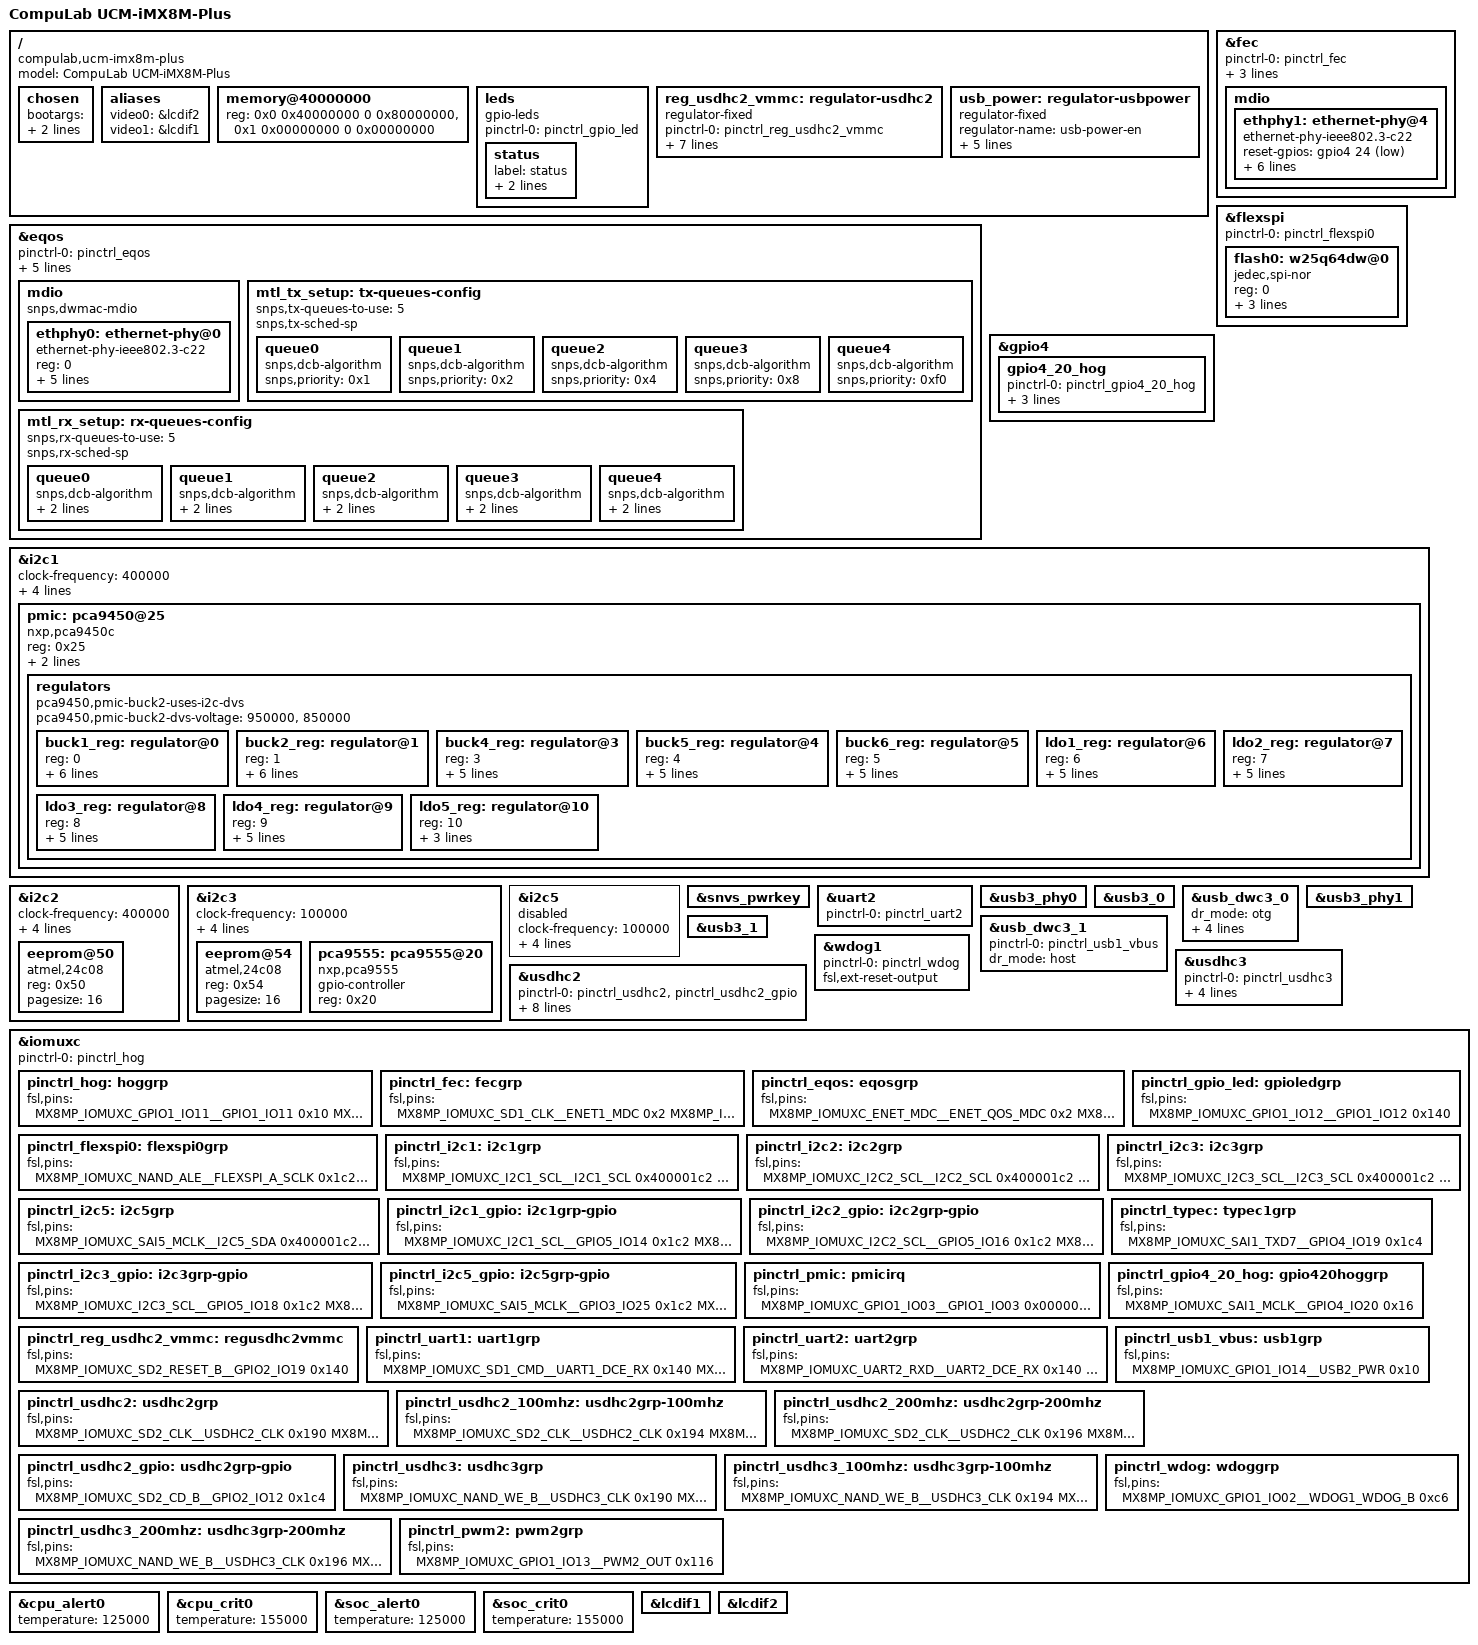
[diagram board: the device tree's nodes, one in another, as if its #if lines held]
// SPDX-License-Identifier: (GPL-2.0+ OR MIT)
/*
 * Copyright 2021 CompuLab
 */

/dts-v1/;

#include <dt-bindings/usb/pd.h>
#include "imx8mp.dtsi"

/ {
	model = "CompuLab UCM-iMX8M-Plus";
	compatible = "compulab,ucm-imx8m-plus", "fsl,imx8mp";

	chosen {
		bootargs = "console=ttymxc1,115200 earlycon=ec_imx6q,0x30890000,115200 console=tty0";
		stdout-path = &uart2;
	};
	aliases {
		video0 = &lcdif2;
		video1 = &lcdif1;
	};

	memory@40000000 {
		device_type = "memory";
		reg = <0x0 0x40000000 0 0x80000000>,
		      <0x1 0x00000000 0 0x00000000>;
	};

	leds {
		compatible = "gpio-leds";
		pinctrl-names = "default";
		pinctrl-0 = <&pinctrl_gpio_led>;

		status {
			label = "status";
			gpios = <&gpio1 12 GPIO_ACTIVE_LOW>;
			default-state = "on"; /* LED GREEN */
		};
	};

	reg_usdhc2_vmmc: regulator-usdhc2 {
		compatible = "regulator-fixed";
		pinctrl-names = "default";
		pinctrl-0 = <&pinctrl_reg_usdhc2_vmmc>;
		regulator-name = "VSD_3V3";
		regulator-min-microvolt = <3300000>;
		regulator-max-microvolt = <3300000>;
		gpio = <&gpio2 19 GPIO_ACTIVE_HIGH>;
		enable-active-high;
		startup-delay-us = <100>;
		off-on-delay-us = <12000>;
	};
#ifdef CONFIG_SBEV_UCMIMX8PLUS
	usb_power: regulator-usbpower {
		compatible = "regulator-fixed";
		regulator-name = "usb-power-en";
		regulator-min-microvolt = <3300000>;
		regulator-max-microvolt = <3300000>;
		gpio = <&pca9555 1 GPIO_ACTIVE_HIGH>;
		enable-active-high;
		regulator-always-on;
	};
#endif
};

&fec {
	pinctrl-names = "default";
	pinctrl-0 = <&pinctrl_fec>;
	phy-mode = "rgmii-rxid";
	phy-handle = <&ethphy1>;
	fsl,magic-packet;
	status = "okay";

	mdio {
		#address-cells = <1>;
		#size-cells = <0>;

		ethphy1: ethernet-phy@4 {
			compatible = "ethernet-phy-ieee802.3-c22";
			reset-gpios = <&gpio4 24 GPIO_ACTIVE_LOW>;
			reg = <4>;
			reset-assert-us = <10000>;
			reset-deassert-us = <80000>;
			eee-broken-1000t;
			realtek,aldps-enable;
			realtek,clkout-disable;
		};
	};
};

&eqos {
	pinctrl-names = "default";
	pinctrl-0 = <&pinctrl_eqos>;
	phy-mode = "rgmii-id";
	phy-handle = <&ethphy0>;
	snps,force_thresh_dma_mode;
	snps,mtl-tx-config = <&mtl_tx_setup>;
	snps,mtl-rx-config = <&mtl_rx_setup>;
	status = "okay";

	mdio {
		compatible = "snps,dwmac-mdio";
		#address-cells = <1>;
		#size-cells = <0>;

		ethphy0: ethernet-phy@0 {
			compatible = "ethernet-phy-ieee802.3-c22";
			reg = <0>;
			eee-broken-1000t;
			reset-gpios = <&gpio1 10 GPIO_ACTIVE_LOW>;
			reset-assert-us = <15000>;
			reset-deassert-us = <100000>;
			realtek,clkout-disable;
		};
	};

	mtl_tx_setup: tx-queues-config {
		snps,tx-queues-to-use = <5>;
		snps,tx-sched-sp;

		queue0 {
			snps,dcb-algorithm;
			snps,priority = <0x1>;
		};

		queue1 {
			snps,dcb-algorithm;
			snps,priority = <0x2>;
		};

		queue2 {
			snps,dcb-algorithm;
			snps,priority = <0x4>;
		};

		queue3 {
			snps,dcb-algorithm;
			snps,priority = <0x8>;
		};

		queue4 {
			snps,dcb-algorithm;
			snps,priority = <0xf0>;
		};
	};

	mtl_rx_setup: rx-queues-config {
		snps,rx-queues-to-use = <5>;
		snps,rx-sched-sp;

		queue0 {
			snps,dcb-algorithm;
			snps,priority = <0x1>;
			snps,map-to-dma-channel = <0>;
		};

		queue1 {
			snps,dcb-algorithm;
			snps,priority = <0x2>;
			snps,map-to-dma-channel = <1>;
		};

		queue2 {
			snps,dcb-algorithm;
			snps,priority = <0x4>;
			snps,map-to-dma-channel = <2>;
		};

		queue3 {
			snps,dcb-algorithm;
			snps,priority = <0x8>;
			snps,map-to-dma-channel = <3>;
		};

		queue4 {
			snps,dcb-algorithm;
			snps,priority = <0xf0>;
			snps,map-to-dma-channel = <4>;
		};
	};
};

&flexspi {
	pinctrl-names = "default";
	pinctrl-0 = <&pinctrl_flexspi0>;
	status = "okay";

	flash0: w25q64dw@0 {
		reg = <0>;
		#address-cells = <1>;
		#size-cells = <1>;
		compatible = "jedec,spi-nor";
		spi-max-frequency = <80000000>;
		spi-tx-bus-width = <4>;
		spi-rx-bus-width = <4>;
	};
};

&gpio4 {
	gpio4_20_hog {
		pinctrl-names = "default";
		pinctrl-0 = <&pinctrl_gpio4_20_hog>;
		gpio-hog;
		gpios = <20 GPIO_ACTIVE_HIGH>;
		output-high;
	};
};

&i2c1 {
	clock-frequency = <400000>;
	pinctrl-names = "default", "gpio";
	pinctrl-0 = <&pinctrl_i2c1>;
	pinctrl-1 = <&pinctrl_i2c1_gpio>;
	scl-gpios = <&gpio5 14 GPIO_ACTIVE_HIGH>;
	sda-gpios = <&gpio5 15 GPIO_ACTIVE_HIGH>;
	status = "okay";

	pmic: pca9450@25 {
		reg = <0x25>;
		compatible = "nxp,pca9450c";
		/* PMIC PCA9450 PMIC_nINT GPIO1_IO3 */
		pinctrl-0 = <&pinctrl_pmic>;
		gpio_intr = <&gpio1 3 GPIO_ACTIVE_LOW>;

		regulators {
			#address-cells = <1>;
			#size-cells = <0>;

			pca9450,pmic-buck2-uses-i2c-dvs;
			/* Run/Standby voltage */
			pca9450,pmic-buck2-dvs-voltage = <950000>, <850000>;

			buck1_reg: regulator@0 {
				reg = <0>;
				regulator-compatible = "buck1";
				regulator-min-microvolt = <600000>;
				regulator-max-microvolt = <2187500>;
				regulator-boot-on;
				regulator-always-on;
				regulator-ramp-delay = <3125>;
			};

			buck2_reg: regulator@1 {
				reg = <1>;
				regulator-compatible = "buck2";
				regulator-min-microvolt = <600000>;
				regulator-max-microvolt = <2187500>;
				regulator-boot-on;
				regulator-always-on;
				regulator-ramp-delay = <3125>;
			};

			buck4_reg: regulator@3 {
				reg = <3>;
				regulator-compatible = "buck4";
				regulator-min-microvolt = <600000>;
				regulator-max-microvolt = <3400000>;
				regulator-boot-on;
				regulator-always-on;
			};

			buck5_reg: regulator@4 {
				reg = <4>;
				regulator-compatible = "buck5";
				regulator-min-microvolt = <600000>;
				regulator-max-microvolt = <3400000>;
				regulator-boot-on;
				regulator-always-on;
			};

			buck6_reg: regulator@5 {
				reg = <5>;
				regulator-compatible = "buck6";
				regulator-min-microvolt = <600000>;
				regulator-max-microvolt = <3400000>;
				regulator-boot-on;
				regulator-always-on;
			};

			ldo1_reg: regulator@6 {
				reg = <6>;
				regulator-compatible = "ldo1";
				regulator-min-microvolt = <1600000>;
				regulator-max-microvolt = <3300000>;
				regulator-boot-on;
				regulator-always-on;
			};

			ldo2_reg: regulator@7 {
				reg = <7>;
				regulator-compatible = "ldo2";
				regulator-min-microvolt = <800000>;
				regulator-max-microvolt = <1150000>;
				regulator-boot-on;
				regulator-always-on;
			};

			ldo3_reg: regulator@8 {
				reg = <8>;
				regulator-compatible = "ldo3";
				regulator-min-microvolt = <800000>;
				regulator-max-microvolt = <3300000>;
				regulator-boot-on;
				regulator-always-on;
			};

			ldo4_reg: regulator@9 {
				reg = <9>;
				regulator-compatible = "ldo4";
				regulator-min-microvolt = <800000>;
				regulator-max-microvolt = <1800000>;
				regulator-boot-on;
				regulator-always-on;
			};

			ldo5_reg: regulator@10 {
				reg = <10>;
				regulator-compatible = "ldo5";
				regulator-min-microvolt = <1800000>;
				regulator-max-microvolt = <3300000>;
			};
		};
	};
};

&i2c2 {
	clock-frequency = <400000>;
	pinctrl-names = "default", "gpio";
	pinctrl-0 = <&pinctrl_i2c2>;
	pinctrl-1 = <&pinctrl_i2c2_gpio>;
	scl-gpios = <&gpio5 16 GPIO_ACTIVE_HIGH>;
	sda-gpios = <&gpio5 17 GPIO_ACTIVE_HIGH>;
	status = "okay";

	eeprom@50 {
		compatible = "atmel,24c08";
		reg = <0x50>;
		pagesize = <16>;
	};
};

&i2c3 {
	clock-frequency = <100000>;
	pinctrl-names = "default", "gpio";
	pinctrl-0 = <&pinctrl_i2c3>;
	pinctrl-1 = <&pinctrl_i2c3_gpio>;
	scl-gpios = <&gpio5 18 GPIO_ACTIVE_HIGH>;
	sda-gpios = <&gpio5 19 GPIO_ACTIVE_HIGH>;
	status = "okay";

};

#ifdef CONFIG_SBEV_UCMIMX8PLUS
&i2c3
#else
&i2c2
#endif
{
	eeprom@54 {
		compatible = "atmel,24c08";
		reg = <0x54>;
		pagesize = <16>;
	};

	pca9555:pca9555@20 {
		compatible = "nxp,pca9555";
		gpio-controller;
		#gpio-cells = <2>;
		reg = <0x20>;
	};
};

&i2c5 {
	clock-frequency = <100000>;
	pinctrl-names = "default", "gpio";
	pinctrl-0 = <&pinctrl_i2c5>;
	pinctrl-1 = <&pinctrl_i2c5_gpio>;
	scl-gpios = <&gpio3 21 GPIO_ACTIVE_HIGH>;
	sda-gpios = <&gpio3 25 GPIO_ACTIVE_HIGH>;
	status = "disabled";

};

&snvs_pwrkey {
	status = "okay";
};

&uart2 {
	/* console */
	pinctrl-names = "default";
	pinctrl-0 = <&pinctrl_uart2>;
	status = "okay";
};

&usb3_phy0 {
	status = "okay";
};

&usb3_0 {
	status = "okay";
};

&usb_dwc3_0 {
	dr_mode = "otg";
	hnp-disable;
	srp-disable;
	adp-disable;
	usb-role-switch;
	status = "okay";
};

&usb3_phy1 {
	status = "okay";
};

&usb3_1 {
	status = "okay";
};

&usb_dwc3_1 {
	pinctrl-names = "default";
	pinctrl-0 = <&pinctrl_usb1_vbus>;
	dr_mode = "host";
	status = "okay";
};

&usdhc2 {
	pinctrl-names = "default", "state_100mhz", "state_200mhz";
	pinctrl-0 = <&pinctrl_usdhc2>, <&pinctrl_usdhc2_gpio>;
	pinctrl-1 = <&pinctrl_usdhc2_100mhz>, <&pinctrl_usdhc2_gpio>;
	pinctrl-2 = <&pinctrl_usdhc2_200mhz>, <&pinctrl_usdhc2_gpio>;
	cd-gpios = <&gpio2 12 GPIO_ACTIVE_LOW>;
	vmmc-supply = <&reg_usdhc2_vmmc>;
	bus-width = <4>;
	no-1-8-v;
	status = "okay";
};

&usdhc3 {
	pinctrl-names = "default", "state_100mhz", "state_200mhz";
	pinctrl-0 = <&pinctrl_usdhc3>;
	pinctrl-1 = <&pinctrl_usdhc3_100mhz>;
	pinctrl-2 = <&pinctrl_usdhc3_200mhz>;
	bus-width = <8>;
	non-removable;
	status = "okay";
};

&wdog1 {
	pinctrl-names = "default";
	pinctrl-0 = <&pinctrl_wdog>;
	fsl,ext-reset-output;
	status = "okay";
};

&iomuxc {
	pinctrl-names = "default";
	pinctrl-0 = <&pinctrl_hog>;

	pinctrl_hog: hoggrp {
		fsl,pins = <
			MX8MP_IOMUXC_GPIO1_IO11__GPIO1_IO11	0x10
			MX8MP_IOMUXC_GPIO1_IO13__GPIO1_IO13	0x10
		>;
	};

	pinctrl_fec: fecgrp {
		fsl,pins = <
			MX8MP_IOMUXC_SD1_CLK__ENET1_MDC			0x2
			MX8MP_IOMUXC_SD1_CMD__ENET1_MDIO		0x2
			MX8MP_IOMUXC_SD1_DATA1__ENET1_RGMII_TD0		0x16
			MX8MP_IOMUXC_SD1_DATA0__ENET1_RGMII_TD1		0x16
			MX8MP_IOMUXC_SAI1_TXD2__ENET1_RGMII_TD2		0x16
			MX8MP_IOMUXC_SAI1_TXD3__ENET1_RGMII_TD3		0x16
			MX8MP_IOMUXC_SAI1_TXD4__ENET1_RGMII_TX_CTL	0x16
			MX8MP_IOMUXC_SAI1_TXD5__ENET1_RGMII_TXC		0x16

			MX8MP_IOMUXC_SD1_DATA2__ENET1_RGMII_RD0		0x90
			MX8MP_IOMUXC_SD1_DATA3__ENET1_RGMII_RD1		0x90
			MX8MP_IOMUXC_SAI1_RXD6__ENET1_RGMII_RD2		0x90
			MX8MP_IOMUXC_SAI1_RXD7__ENET1_RGMII_RD3		0x90
			MX8MP_IOMUXC_SAI1_TXC__ENET1_RGMII_RXC		0x90
			MX8MP_IOMUXC_SAI1_TXFS__ENET1_RGMII_RX_CTL	0x90

			/* gpio */
			MX8MP_IOMUXC_SAI2_RXFS__GPIO4_IO21		0x10 /* INT */
			MX8MP_IOMUXC_SAI2_TXFS__GPIO4_IO24		0x10 /* RST */
		>;
	};

	pinctrl_eqos: eqosgrp {
		fsl,pins = <
			MX8MP_IOMUXC_ENET_MDC__ENET_QOS_MDC	0x2
			MX8MP_IOMUXC_ENET_MDIO__ENET_QOS_MDIO	0x2
			MX8MP_IOMUXC_ENET_RD0__ENET_QOS_RGMII_RD0	0x90
			MX8MP_IOMUXC_ENET_RD1__ENET_QOS_RGMII_RD1	0x90
			MX8MP_IOMUXC_ENET_RD2__ENET_QOS_RGMII_RD2	0x90
			MX8MP_IOMUXC_ENET_RD3__ENET_QOS_RGMII_RD3	0x90
			MX8MP_IOMUXC_ENET_RXC__CCM_ENET_QOS_CLOCK_GENERATE_RX_CLK	0x90
			MX8MP_IOMUXC_ENET_RX_CTL__ENET_QOS_RGMII_RX_CTL	0x90
			MX8MP_IOMUXC_ENET_TD0__ENET_QOS_RGMII_TD0		0x16
			MX8MP_IOMUXC_ENET_TD1__ENET_QOS_RGMII_TD1		0x16
			MX8MP_IOMUXC_ENET_TD2__ENET_QOS_RGMII_TD2		0x16
			MX8MP_IOMUXC_ENET_TD3__ENET_QOS_RGMII_TD3		0x16
			MX8MP_IOMUXC_ENET_TX_CTL__ENET_QOS_RGMII_TX_CTL	0x16
			MX8MP_IOMUXC_ENET_TXC__CCM_ENET_QOS_CLOCK_GENERATE_TX_CLK	0x16
			MX8MP_IOMUXC_GPIO1_IO10__GPIO1_IO10	0x10
		>;
	};

	pinctrl_flexspi0: flexspi0grp {
		fsl,pins = <
			MX8MP_IOMUXC_NAND_ALE__FLEXSPI_A_SCLK		0x1c2
			MX8MP_IOMUXC_NAND_CE0_B__FLEXSPI_A_SS0_B	0x82
			MX8MP_IOMUXC_NAND_DATA00__FLEXSPI_A_DATA00	0x82
			MX8MP_IOMUXC_NAND_DATA01__FLEXSPI_A_DATA01	0x82
			MX8MP_IOMUXC_NAND_DATA02__FLEXSPI_A_DATA02	0x82
			MX8MP_IOMUXC_NAND_DATA03__FLEXSPI_A_DATA03	0x82
		>;
	};

	pinctrl_gpio_led: gpioledgrp {
		fsl,pins = <
			MX8MP_IOMUXC_GPIO1_IO12__GPIO1_IO12	0x140
		>;
	};

	pinctrl_i2c1: i2c1grp {
		fsl,pins = <
			MX8MP_IOMUXC_I2C1_SCL__I2C1_SCL		0x400001c2
			MX8MP_IOMUXC_I2C1_SDA__I2C1_SDA		0x400001c2
		>;
	};

	pinctrl_i2c2: i2c2grp {
		fsl,pins = <
			MX8MP_IOMUXC_I2C2_SCL__I2C2_SCL			0x400001c2
			MX8MP_IOMUXC_I2C2_SDA__I2C2_SDA			0x400001c2
		>;
	};

	pinctrl_i2c3: i2c3grp {
		fsl,pins = <
			MX8MP_IOMUXC_I2C3_SCL__I2C3_SCL			0x400001c2
			MX8MP_IOMUXC_I2C3_SDA__I2C3_SDA			0x400001c2
		>;
	};

	pinctrl_i2c5: i2c5grp {
		fsl,pins = <
			MX8MP_IOMUXC_SAI5_MCLK__I2C5_SDA		0x400001c2
			MX8MP_IOMUXC_SAI5_RXD0__I2C5_SCL		0x400001c2
		>;
	};

	pinctrl_i2c1_gpio: i2c1grp-gpio {
		fsl,pins = <
			MX8MP_IOMUXC_I2C1_SCL__GPIO5_IO14        	0x1c2
			MX8MP_IOMUXC_I2C1_SDA__GPIO5_IO15        	0x1c2
		>;
	};

	pinctrl_i2c2_gpio: i2c2grp-gpio {
		fsl,pins = <
			MX8MP_IOMUXC_I2C2_SCL__GPIO5_IO16        	0x1c2
			MX8MP_IOMUXC_I2C2_SDA__GPIO5_IO17        	0x1c2
		>;
	};

	pinctrl_i2c3_gpio: i2c3grp-gpio {
		fsl,pins = <
			MX8MP_IOMUXC_I2C3_SCL__GPIO5_IO18        	0x1c2
			MX8MP_IOMUXC_I2C3_SDA__GPIO5_IO19        	0x1c2
		>;
	};

	pinctrl_i2c5_gpio: i2c5grp-gpio {
		fsl,pins = <
			MX8MP_IOMUXC_SAI5_MCLK__GPIO3_IO25       	0x1c2
			MX8MP_IOMUXC_SAI5_RXD0__GPIO3_IO21        	0x1c2
		>;
	};

	pinctrl_pmic: pmicirq {
		fsl,pins = <
			MX8MP_IOMUXC_GPIO1_IO03__GPIO1_IO03	0x000001c0
		>;
	};

	pinctrl_typec: typec1grp {
		fsl,pins = <
			MX8MP_IOMUXC_SAI1_TXD7__GPIO4_IO19	0x1c4
		>;
	};

	pinctrl_gpio4_20_hog: gpio420hoggrp {
		fsl,pins = <
			MX8MP_IOMUXC_SAI1_MCLK__GPIO4_IO20	0x16
		>;
	};

	pinctrl_reg_usdhc2_vmmc: regusdhc2vmmc {
		fsl,pins = <
			MX8MP_IOMUXC_SD2_RESET_B__GPIO2_IO19	0x140
		>;
	};

	pinctrl_uart1: uart1grp {
		fsl,pins = <
			MX8MP_IOMUXC_SD1_CMD__UART1_DCE_RX	0x140
			MX8MP_IOMUXC_SAI2_RXFS__UART1_DCE_TX	0x140
		>;
	};

	pinctrl_uart2: uart2grp {
		fsl,pins = <
			MX8MP_IOMUXC_UART2_RXD__UART2_DCE_RX	0x140
			MX8MP_IOMUXC_UART2_TXD__UART2_DCE_TX	0x140
		>;
	};

	pinctrl_usb1_vbus: usb1grp {
		fsl,pins = <
			MX8MP_IOMUXC_GPIO1_IO14__USB2_PWR	0x10
		>;
	};

	pinctrl_usdhc2: usdhc2grp {
		fsl,pins = <
			MX8MP_IOMUXC_SD2_CLK__USDHC2_CLK	0x190
			MX8MP_IOMUXC_SD2_CMD__USDHC2_CMD	0x1d0
			MX8MP_IOMUXC_SD2_DATA0__USDHC2_DATA0	0x1d0
			MX8MP_IOMUXC_SD2_DATA1__USDHC2_DATA1	0x1d0
			MX8MP_IOMUXC_SD2_DATA2__USDHC2_DATA2	0x1d0
			MX8MP_IOMUXC_SD2_DATA3__USDHC2_DATA3	0x1d0
			MX8MP_IOMUXC_GPIO1_IO04__USDHC2_VSELECT	0xc0
		>;
	};

	pinctrl_usdhc2_100mhz: usdhc2grp-100mhz {
		fsl,pins = <
			MX8MP_IOMUXC_SD2_CLK__USDHC2_CLK	0x194
			MX8MP_IOMUXC_SD2_CMD__USDHC2_CMD	0x1d4
			MX8MP_IOMUXC_SD2_DATA0__USDHC2_DATA0	0x1d4
			MX8MP_IOMUXC_SD2_DATA1__USDHC2_DATA1	0x1d4
			MX8MP_IOMUXC_SD2_DATA2__USDHC2_DATA2	0x1d4
			MX8MP_IOMUXC_SD2_DATA3__USDHC2_DATA3	0x1d4
			MX8MP_IOMUXC_GPIO1_IO04__USDHC2_VSELECT 0xc0
		>;
	};

	pinctrl_usdhc2_200mhz: usdhc2grp-200mhz {
		fsl,pins = <
			MX8MP_IOMUXC_SD2_CLK__USDHC2_CLK	0x196
			MX8MP_IOMUXC_SD2_CMD__USDHC2_CMD	0x1d6
			MX8MP_IOMUXC_SD2_DATA0__USDHC2_DATA0	0x1d6
			MX8MP_IOMUXC_SD2_DATA1__USDHC2_DATA1	0x1d6
			MX8MP_IOMUXC_SD2_DATA2__USDHC2_DATA2	0x1d6
			MX8MP_IOMUXC_SD2_DATA3__USDHC2_DATA3	0x1d6
			MX8MP_IOMUXC_GPIO1_IO04__USDHC2_VSELECT 0xc0
		>;
	};

	pinctrl_usdhc2_gpio: usdhc2grp-gpio {
		fsl,pins = <
			MX8MP_IOMUXC_SD2_CD_B__GPIO2_IO12	0x1c4
		>;
	};

	pinctrl_usdhc3: usdhc3grp {
		fsl,pins = <
			MX8MP_IOMUXC_NAND_WE_B__USDHC3_CLK	0x190
			MX8MP_IOMUXC_NAND_WP_B__USDHC3_CMD	0x1d0
			MX8MP_IOMUXC_NAND_DATA04__USDHC3_DATA0	0x1d0
			MX8MP_IOMUXC_NAND_DATA05__USDHC3_DATA1	0x1d0
			MX8MP_IOMUXC_NAND_DATA06__USDHC3_DATA2	0x1d0
			MX8MP_IOMUXC_NAND_DATA07__USDHC3_DATA3	0x1d0
			MX8MP_IOMUXC_NAND_RE_B__USDHC3_DATA4	0x1d0
			MX8MP_IOMUXC_NAND_CE2_B__USDHC3_DATA5	0x1d0
			MX8MP_IOMUXC_NAND_CE3_B__USDHC3_DATA6	0x1d0
			MX8MP_IOMUXC_NAND_CLE__USDHC3_DATA7	0x1d0
			MX8MP_IOMUXC_NAND_CE1_B__USDHC3_STROBE	0x190
		>;
	};

	pinctrl_usdhc3_100mhz: usdhc3grp-100mhz {
		fsl,pins = <
			MX8MP_IOMUXC_NAND_WE_B__USDHC3_CLK	0x194
			MX8MP_IOMUXC_NAND_WP_B__USDHC3_CMD	0x1d4
			MX8MP_IOMUXC_NAND_DATA04__USDHC3_DATA0	0x1d4
			MX8MP_IOMUXC_NAND_DATA05__USDHC3_DATA1	0x1d4
			MX8MP_IOMUXC_NAND_DATA06__USDHC3_DATA2	0x1d4
			MX8MP_IOMUXC_NAND_DATA07__USDHC3_DATA3	0x1d4
			MX8MP_IOMUXC_NAND_RE_B__USDHC3_DATA4	0x1d4
			MX8MP_IOMUXC_NAND_CE2_B__USDHC3_DATA5	0x1d4
			MX8MP_IOMUXC_NAND_CE3_B__USDHC3_DATA6	0x1d4
			MX8MP_IOMUXC_NAND_CLE__USDHC3_DATA7	0x1d4
			MX8MP_IOMUXC_NAND_CE1_B__USDHC3_STROBE	0x194
		>;
	};

	pinctrl_usdhc3_200mhz: usdhc3grp-200mhz {
		fsl,pins = <
			MX8MP_IOMUXC_NAND_WE_B__USDHC3_CLK	0x196
			MX8MP_IOMUXC_NAND_WP_B__USDHC3_CMD	0x1d6
			MX8MP_IOMUXC_NAND_DATA04__USDHC3_DATA0	0x1d6
			MX8MP_IOMUXC_NAND_DATA05__USDHC3_DATA1	0x1d6
			MX8MP_IOMUXC_NAND_DATA06__USDHC3_DATA2	0x1d6
			MX8MP_IOMUXC_NAND_DATA07__USDHC3_DATA3	0x1d6
			MX8MP_IOMUXC_NAND_RE_B__USDHC3_DATA4	0x1d6
			MX8MP_IOMUXC_NAND_CE2_B__USDHC3_DATA5	0x1d6
			MX8MP_IOMUXC_NAND_CE3_B__USDHC3_DATA6	0x1d6
			MX8MP_IOMUXC_NAND_CLE__USDHC3_DATA7	0x1d6
			MX8MP_IOMUXC_NAND_CE1_B__USDHC3_STROBE	0x196
		>;
	};

	pinctrl_wdog: wdoggrp {
		fsl,pins = <
			MX8MP_IOMUXC_GPIO1_IO02__WDOG1_WDOG_B	0xc6
		>;
	};

	pinctrl_pwm2: pwm2grp {
		fsl,pins = <
			MX8MP_IOMUXC_GPIO1_IO13__PWM2_OUT	0x116
		>;
	};
};

&cpu_alert0 {
    temperature = <125000>;
};

&cpu_crit0 {
    temperature = <155000>;
};

&soc_alert0 {
    temperature = <125000>;
};

&soc_crit0 {
    temperature = <155000>;
};

#include "compulab-imx8m-plus-lcdif1.dtsi"
&lcdif1 {
	status = "okay";
};

#include "compulab-imx8m-plus-lcdif2.dtsi"
&lcdif2 {
	status = "okay";
};
